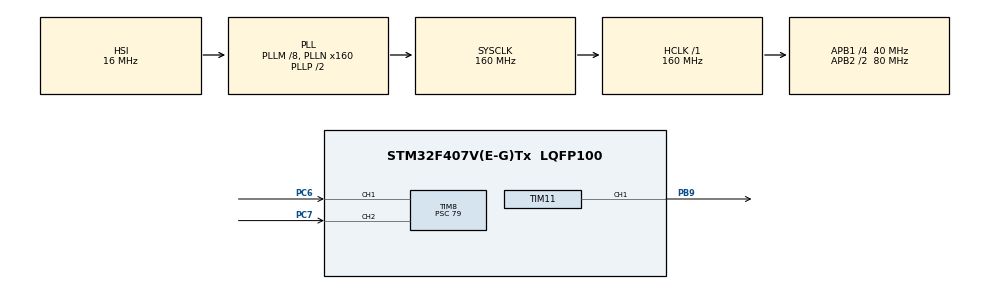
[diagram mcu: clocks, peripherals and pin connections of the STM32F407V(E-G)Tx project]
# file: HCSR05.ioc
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Mcu.Family=STM32F4
Mcu.Name=STM32F407V(E-G)Tx
Mcu.Package=LQFP100
NVIC.PriorityGroup=NVIC_PRIORITYGROUP_4
PB9.Signal=S_TIM11_CH1
PC6.Signal=S_TIM8_CH1
PC7.Signal=S_TIM8_CH2
ProjectManager.HeapSize=0x200
ProjectManager.StackSize=0x400
ProjectManager.TargetToolchain=MDK-ARM V5.32
RCC.48MHZClocksFreq_Value=80000000
RCC.AHBFreq_Value=160000000
RCC.APB1CLKDivider=RCC_HCLK_DIV4
RCC.APB1Freq_Value=40000000
RCC.APB1TimFreq_Value=80000000
RCC.APB2CLKDivider=RCC_HCLK_DIV2
RCC.APB2Freq_Value=80000000
RCC.APB2TimFreq_Value=160000000
RCC.CortexFreq_Value=160000000
RCC.HCLKFreq_Value=160000000
RCC.HSE_VALUE=25000000
RCC.HSI_VALUE=16000000
RCC.LSE_VALUE=32768
RCC.PLLM=8
RCC.PLLN=160
RCC.SYSCLKFreq_VALUE=160000000
RCC.SYSCLKSource=RCC_SYSCLKSOURCE_PLLCLK
RCC.VCOOutputFreq_Value=320000000
SH.S_TIM11_CH1.0=TIM11_CH1,PWM Generation1 CH1
SH.S_TIM8_CH1.0=TIM8_CH1,Input_Capture1_from_TI1
SH.S_TIM8_CH2.0=TIM8_CH2,Input_Capture2_from_TI2
SH.S_TIM8_CH2.1=TIM8_CH2,TriggerSource_TI2FP2
TIM11.Channel=TIM_CHANNEL_1
TIM11.Period=39999
TIM11.Prescaler=199
TIM8.Channel-Input_Capture1_from_TI1=TIM_CHANNEL_1
TIM8.Channel-Input_Capture2_from_TI2=TIM_CHANNEL_2
TIM8.ICPolarity_CH1=TIM_INPUTCHANNELPOLARITY_BOTHEDGE
TIM8.ICPolarity_CH2=TIM_INPUTCHANNELPOLARITY_BOTHEDGE
TIM8.Prescaler=79
VP_TIM11_VS_ClockSourceINT.Mode=Enable_Timer
VP_TIM8_VS_ControllerModeReset.Mode=Reset Mode
board=custom

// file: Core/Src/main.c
/* USER CODE BEGIN Header */
/**
  ******************************************************************************
  * @file           : main.c
  * @brief          : Main program body
  ******************************************************************************
  * @attention
  *
  * Copyright (c) 2022 STMicroelectronics.
  * All rights reserved.
  *
  * This software is licensed under terms that can be found in the LICENSE file
  * in the root directory of this software component.
  * If no LICENSE file comes with this software, it is provided AS-IS.
  *
  ******************************************************************************
  */
/* USER CODE END Header */
#include "main.h"
#include "tim.h"
#include "gpio.h"

/* USER CODE BEGIN Includes */
#include "stdio.h"
/* USER CODE END Includes */

void SystemClock_Config(void);

/* USER CODE BEGIN 0 */
uint32_t echo1,echo2, delay;
float dist1,dist2;
/* USER CODE END 0 */

int main(void)
{

  /* MCU Configuration--------------------------------------------------------*/

  /* Reset of all peripherals, Initializes the Flash interface and the Systick. */
  HAL_Init();

  /* Configure the system clock */
  SystemClock_Config();

  /* Initialize all configured peripherals */
  MX_GPIO_Init();
  MX_TIM8_Init();
  MX_TIM11_Init();
  /* USER CODE BEGIN 2 */
	HAL_TIM_Base_Start(&htim11);
	HAL_TIM_Base_Start(&htim11);
	HAL_TIM_PWM_Start(&htim11, TIM_CHANNEL_1);
	HAL_TIM_IC_Start(&htim8,TIM_CHANNEL_1);
	HAL_TIM_IC_Start(&htim8,TIM_CHANNEL_2);
	TIM11->CCR1 = 3;
  /* USER CODE END 2 */

  /* Infinite loop */
  /* USER CODE BEGIN WHILE */
  while (1)
  {
		if(HAL_GetTick() - delay >= 100)
		{
			delay = HAL_GetTick();
			echo1 = HAL_TIM_ReadCapturedValue(&htim8, TIM_CHANNEL_1);
			echo2 = HAL_TIM_ReadCapturedValue(&htim8, TIM_CHANNEL_2);
			dist1 = echo2/116.0f;
		}
    /* USER CODE END WHILE */

  }
}

void SystemClock_Config(void)
{
  RCC_OscInitTypeDef RCC_OscInitStruct = {0};
  RCC_ClkInitTypeDef RCC_ClkInitStruct = {0};

  /** Configure the main internal regulator output voltage
  */
  __HAL_RCC_PWR_CLK_ENABLE();
  __HAL_PWR_VOLTAGESCALING_CONFIG(PWR_REGULATOR_VOLTAGE_SCALE1);
  /** Initializes the RCC Oscillators according to the specified parameters
  * in the RCC_OscInitTypeDef structure.
  */
  RCC_OscInitStruct.OscillatorType = RCC_OSCILLATORTYPE_HSI;
  RCC_OscInitStruct.HSIState = RCC_HSI_ON;
  RCC_OscInitStruct.HSICalibrationValue = RCC_HSICALIBRATION_DEFAULT;
  RCC_OscInitStruct.PLL.PLLState = RCC_PLL_ON;
  RCC_OscInitStruct.PLL.PLLSource = RCC_PLLSOURCE_HSI;
  RCC_OscInitStruct.PLL.PLLM = 8;
  RCC_OscInitStruct.PLL.PLLN = 160;
  RCC_OscInitStruct.PLL.PLLP = RCC_PLLP_DIV2;
  RCC_OscInitStruct.PLL.PLLQ = 4;
  if (HAL_RCC_OscConfig(&RCC_OscInitStruct) != HAL_OK)
  {
    Error_Handler();
  }
  /** Initializes the CPU, AHB and APB buses clocks
  */
  RCC_ClkInitStruct.ClockType = RCC_CLOCKTYPE_HCLK|RCC_CLOCKTYPE_SYSCLK
                              |RCC_CLOCKTYPE_PCLK1|RCC_CLOCKTYPE_PCLK2;
  RCC_ClkInitStruct.SYSCLKSource = RCC_SYSCLKSOURCE_PLLCLK;
  RCC_ClkInitStruct.AHBCLKDivider = RCC_SYSCLK_DIV1;
  RCC_ClkInitStruct.APB1CLKDivider = RCC_HCLK_DIV4;
  RCC_ClkInitStruct.APB2CLKDivider = RCC_HCLK_DIV2;

  if (HAL_RCC_ClockConfig(&RCC_ClkInitStruct, FLASH_LATENCY_5) != HAL_OK)
  {
    Error_Handler();
  }
}

void Error_Handler(void)
{
  __disable_irq();
  while (1)
  {
  }
}
